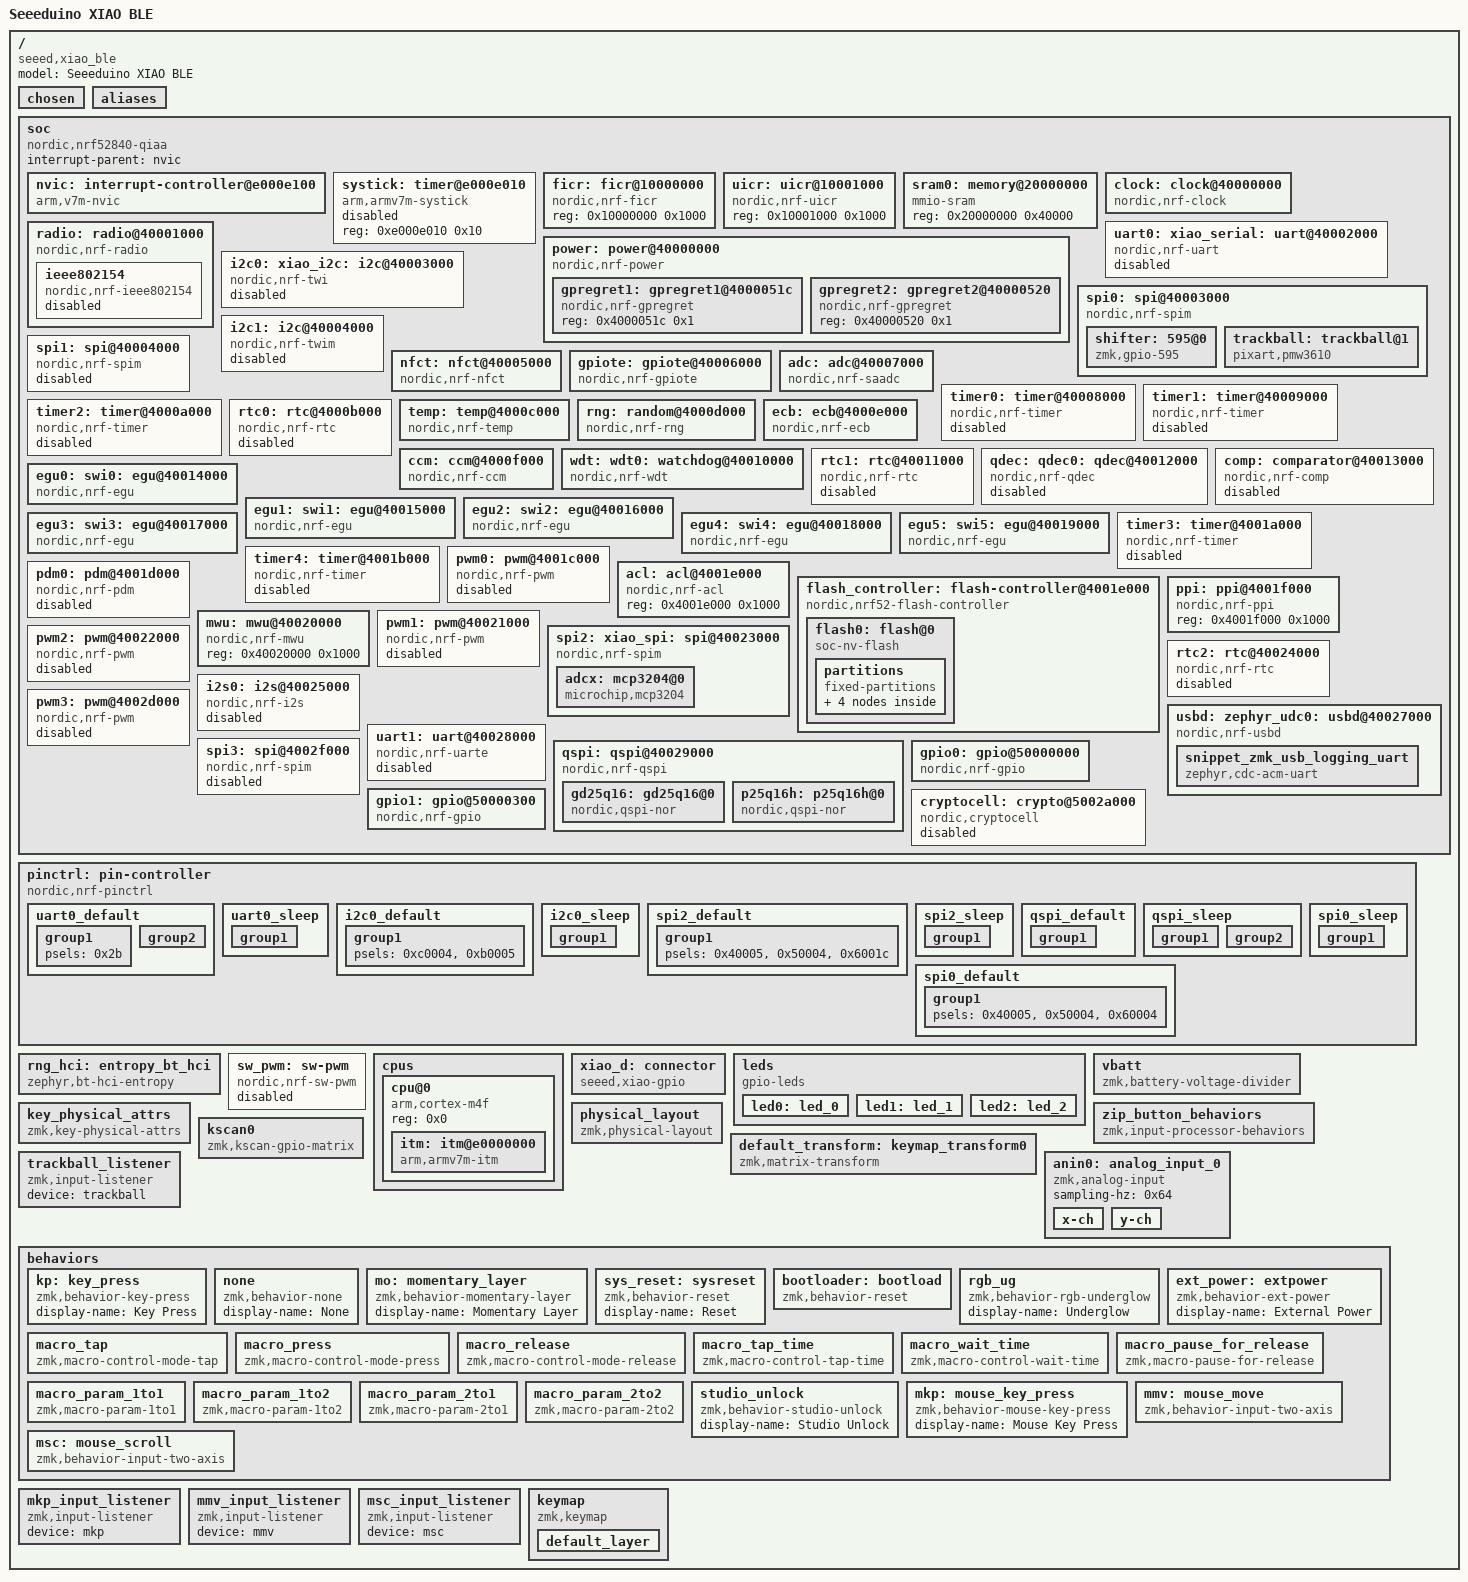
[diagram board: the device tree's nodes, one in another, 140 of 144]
/dts-v1/;

/ {
	#address-cells = < 0x1 >;
	#size-cells = < 0x1 >;
	model = "Seeeduino XIAO BLE";
	compatible = "seeed,xiao_ble";
	chosen {
		zephyr,entropy = &rng;
		zephyr,flash-controller = &flash_controller;
		zephyr,console = &snippet_zmk_usb_logging_uart;
		zephyr,shell-uart = &snippet_zmk_usb_logging_uart;
		zephyr,uart-mcumgr = &uart0;
		zephyr,bt-mon-uart = &uart0;
		zephyr,bt-c2h-uart = &uart0;
		zephyr,sram = &sram0;
		zephyr,flash = &flash0;
		zephyr,code-partition = &code_partition;
		zmk,battery = &vbatt;
		zmk,physical-layout = &physical_layout;
	};
	aliases {
		led0 = &led0;
		led1 = &led1;
		led2 = &led2;
	};
	soc {
		#address-cells = < 0x1 >;
		#size-cells = < 0x1 >;
		compatible = "nordic,nrf52840-qiaa", "nordic,nrf52840", "nordic,nrf52", "simple-bus";
		interrupt-parent = < &nvic >;
		ranges;
		nvic: interrupt-controller@e000e100 {
			#address-cells = < 0x1 >;
			compatible = "arm,v7m-nvic";
			reg = < 0xe000e100 0xc00 >;
			interrupt-controller;
			#interrupt-cells = < 0x2 >;
			arm,num-irq-priority-bits = < 0x3 >;
			phandle = < 0x1 >;
		};
		systick: timer@e000e010 {
			compatible = "arm,armv7m-systick";
			reg = < 0xe000e010 0x10 >;
			status = "disabled";
		};
		ficr: ficr@10000000 {
			compatible = "nordic,nrf-ficr";
			reg = < 0x10000000 0x1000 >;
			status = "okay";
		};
		uicr: uicr@10001000 {
			compatible = "nordic,nrf-uicr";
			reg = < 0x10001000 0x1000 >;
			status = "okay";
		};
		sram0: memory@20000000 {
			compatible = "mmio-sram";
			reg = < 0x20000000 0x40000 >;
		};
		clock: clock@40000000 {
			compatible = "nordic,nrf-clock";
			reg = < 0x40000000 0x1000 >;
			interrupts = < 0x0 0x1 >;
			status = "okay";
		};
		power: power@40000000 {
			compatible = "nordic,nrf-power";
			reg = < 0x40000000 0x1000 >;
			interrupts = < 0x0 0x1 >;
			status = "okay";
			#address-cells = < 0x1 >;
			#size-cells = < 0x1 >;
			gpregret1: gpregret1@4000051c {
				#address-cells = < 0x1 >;
				#size-cells = < 0x1 >;
				compatible = "nordic,nrf-gpregret";
				reg = < 0x4000051c 0x1 >;
				status = "okay";
			};
			gpregret2: gpregret2@40000520 {
				#address-cells = < 0x1 >;
				#size-cells = < 0x1 >;
				compatible = "nordic,nrf-gpregret";
				reg = < 0x40000520 0x1 >;
				status = "okay";
			};
		};
		radio: radio@40001000 {
			compatible = "nordic,nrf-radio";
			reg = < 0x40001000 0x1000 >;
			interrupts = < 0x1 0x1 >;
			status = "okay";
			ieee802154-supported;
			ble-2mbps-supported;
			ble-coded-phy-supported;
			tx-high-power-supported;
			ieee802154: ieee802154 {
				compatible = "nordic,nrf-ieee802154";
				status = "disabled";
			};
		};
		uart0: xiao_serial: uart@40002000 {
			compatible = "nordic,nrf-uart";
			reg = < 0x40002000 0x1000 >;
			interrupts = < 0x2 0x1 >;
			status = "disabled";
			current-speed = < 0x1c200 >;
			pinctrl-0 = < &uart0_default >;
			pinctrl-1 = < &uart0_sleep >;
			pinctrl-names = "default", "sleep";
		};
		i2c0: xiao_i2c: i2c@40003000 {
			compatible = "nordic,nrf-twi";
			#address-cells = < 0x1 >;
			#size-cells = < 0x0 >;
			reg = < 0x40003000 0x1000 >;
			clock-frequency = < 0x186a0 >;
			interrupts = < 0x3 0x1 >;
			easydma-maxcnt-bits = < 0x10 >;
			status = "disabled";
			pinctrl-0 = < &i2c0_default >;
			pinctrl-1 = < &i2c0_sleep >;
			pinctrl-names = "default", "sleep";
		};
		spi0: spi@40003000 {
			compatible = "nordic,nrf-spim";
			#address-cells = < 0x1 >;
			#size-cells = < 0x0 >;
			reg = < 0x40003000 0x1000 >;
			interrupts = < 0x3 0x1 >;
			max-frequency = < 0x7a1200 >;
			easydma-maxcnt-bits = < 0x10 >;
			status = "okay";
			pinctrl-0 = < &spi0_default >;
			pinctrl-1 = < &spi0_sleep >;
			pinctrl-names = "default", "sleep";
			cs-gpios = < &xiao_d 0x3 0x1 >, < &xiao_d 0x6 0x1 >;
			shifter: 595@0 {
				compatible = "zmk,gpio-595";
				status = "okay";
				reg = < 0x0 >;
				gpio-controller;
				spi-max-frequency = < 0x493e0 >;
				#gpio-cells = < 0x2 >;
				ngpios = < 0x20 >;
				phandle = < 0x15 >;
			};
			trackball: trackball@1 {
				compatible = "pixart,pmw3610";
				status = "okay";
				reg = < 0x1 >;
				spi-max-frequency = < 0x1e8480 >;
				irq-gpios = < &xiao_d 0x7 0x11 >;
				cpi = < 0x258 >;
				evt-type = < 0x2 >;
				x-input-code = < 0x0 >;
				y-input-code = < 0x1 >;
				phandle = < 0x16 >;
			};
		};
		i2c1: i2c@40004000 {
			compatible = "nordic,nrf-twim";
			#address-cells = < 0x1 >;
			#size-cells = < 0x0 >;
			reg = < 0x40004000 0x1000 >;
			clock-frequency = < 0x186a0 >;
			interrupts = < 0x4 0x1 >;
			easydma-maxcnt-bits = < 0x10 >;
			status = "disabled";
		};
		spi1: spi@40004000 {
			compatible = "nordic,nrf-spim";
			#address-cells = < 0x1 >;
			#size-cells = < 0x0 >;
			reg = < 0x40004000 0x1000 >;
			interrupts = < 0x4 0x1 >;
			max-frequency = < 0x7a1200 >;
			easydma-maxcnt-bits = < 0x10 >;
			status = "disabled";
		};
		nfct: nfct@40005000 {
			compatible = "nordic,nrf-nfct";
			reg = < 0x40005000 0x1000 >;
			interrupts = < 0x5 0x1 >;
			status = "okay";
		};
		gpiote: gpiote@40006000 {
			compatible = "nordic,nrf-gpiote";
			reg = < 0x40006000 0x1000 >;
			interrupts = < 0x6 0x5 >;
			status = "okay";
		};
		adc: adc@40007000 {
			compatible = "nordic,nrf-saadc";
			reg = < 0x40007000 0x1000 >;
			interrupts = < 0x7 0x1 >;
			status = "okay";
			#io-channel-cells = < 0x1 >;
			phandle = < 0x10 >;
		};
		timer0: timer@40008000 {
			compatible = "nordic,nrf-timer";
			status = "disabled";
			reg = < 0x40008000 0x1000 >;
			cc-num = < 0x4 >;
			max-bit-width = < 0x20 >;
			interrupts = < 0x8 0x1 >;
			prescaler = < 0x0 >;
		};
		timer1: timer@40009000 {
			compatible = "nordic,nrf-timer";
			status = "disabled";
			reg = < 0x40009000 0x1000 >;
			cc-num = < 0x4 >;
			max-bit-width = < 0x20 >;
			interrupts = < 0x9 0x1 >;
			prescaler = < 0x0 >;
			phandle = < 0xd >;
		};
		timer2: timer@4000a000 {
			compatible = "nordic,nrf-timer";
			status = "disabled";
			reg = < 0x4000a000 0x1000 >;
			cc-num = < 0x4 >;
			max-bit-width = < 0x20 >;
			interrupts = < 0xa 0x1 >;
			prescaler = < 0x0 >;
		};
		rtc0: rtc@4000b000 {
			compatible = "nordic,nrf-rtc";
			reg = < 0x4000b000 0x1000 >;
			cc-num = < 0x3 >;
			interrupts = < 0xb 0x1 >;
			status = "disabled";
			clock-frequency = < 0x8000 >;
			prescaler = < 0x1 >;
		};
		temp: temp@4000c000 {
			compatible = "nordic,nrf-temp";
			reg = < 0x4000c000 0x1000 >;
			interrupts = < 0xc 0x1 >;
			status = "okay";
		};
		rng: random@4000d000 {
			compatible = "nordic,nrf-rng";
			reg = < 0x4000d000 0x1000 >;
			interrupts = < 0xd 0x1 >;
			status = "okay";
		};
		ecb: ecb@4000e000 {
			compatible = "nordic,nrf-ecb";
			reg = < 0x4000e000 0x1000 >;
			interrupts = < 0xe 0x1 >;
			status = "okay";
		};
		ccm: ccm@4000f000 {
			compatible = "nordic,nrf-ccm";
			reg = < 0x4000f000 0x1000 >;
			interrupts = < 0xf 0x1 >;
			length-field-length-8-bits;
			status = "okay";
		};
		wdt: wdt0: watchdog@40010000 {
			compatible = "nordic,nrf-wdt";
			reg = < 0x40010000 0x1000 >;
			interrupts = < 0x10 0x1 >;
			status = "okay";
		};
		rtc1: rtc@40011000 {
			compatible = "nordic,nrf-rtc";
			reg = < 0x40011000 0x1000 >;
			cc-num = < 0x4 >;
			interrupts = < 0x11 0x1 >;
			status = "disabled";
			clock-frequency = < 0x8000 >;
			prescaler = < 0x1 >;
		};
		qdec: qdec0: qdec@40012000 {
			compatible = "nordic,nrf-qdec";
			reg = < 0x40012000 0x1000 >;
			interrupts = < 0x12 0x1 >;
			status = "disabled";
		};
		comp: comparator@40013000 {
			compatible = "nordic,nrf-comp";
			reg = < 0x40013000 0x1000 >;
			interrupts = < 0x13 0x1 >;
			status = "disabled";
			#io-channel-cells = < 0x1 >;
		};
		egu0: swi0: egu@40014000 {
			compatible = "nordic,nrf-egu", "nordic,nrf-swi";
			reg = < 0x40014000 0x1000 >;
			interrupts = < 0x14 0x1 >;
			status = "okay";
		};
		egu1: swi1: egu@40015000 {
			compatible = "nordic,nrf-egu", "nordic,nrf-swi";
			reg = < 0x40015000 0x1000 >;
			interrupts = < 0x15 0x1 >;
			status = "okay";
		};
		egu2: swi2: egu@40016000 {
			compatible = "nordic,nrf-egu", "nordic,nrf-swi";
			reg = < 0x40016000 0x1000 >;
			interrupts = < 0x16 0x1 >;
			status = "okay";
		};
		egu3: swi3: egu@40017000 {
			compatible = "nordic,nrf-egu", "nordic,nrf-swi";
			reg = < 0x40017000 0x1000 >;
			interrupts = < 0x17 0x1 >;
			status = "okay";
		};
		egu4: swi4: egu@40018000 {
			compatible = "nordic,nrf-egu", "nordic,nrf-swi";
			reg = < 0x40018000 0x1000 >;
			interrupts = < 0x18 0x1 >;
			status = "okay";
		};
		egu5: swi5: egu@40019000 {
			compatible = "nordic,nrf-egu", "nordic,nrf-swi";
			reg = < 0x40019000 0x1000 >;
			interrupts = < 0x19 0x1 >;
			status = "okay";
		};
		timer3: timer@4001a000 {
			compatible = "nordic,nrf-timer";
			status = "disabled";
			reg = < 0x4001a000 0x1000 >;
			cc-num = < 0x6 >;
			max-bit-width = < 0x20 >;
			interrupts = < 0x1a 0x1 >;
			prescaler = < 0x0 >;
		};
		timer4: timer@4001b000 {
			compatible = "nordic,nrf-timer";
			status = "disabled";
			reg = < 0x4001b000 0x1000 >;
			cc-num = < 0x6 >;
			max-bit-width = < 0x20 >;
			interrupts = < 0x1b 0x1 >;
			prescaler = < 0x0 >;
		};
		pwm0: pwm@4001c000 {
			compatible = "nordic,nrf-pwm";
			reg = < 0x4001c000 0x1000 >;
			interrupts = < 0x1c 0x1 >;
			status = "disabled";
			#pwm-cells = < 0x3 >;
		};
		pdm0: pdm@4001d000 {
			compatible = "nordic,nrf-pdm";
			reg = < 0x4001d000 0x1000 >;
			interrupts = < 0x1d 0x1 >;
			status = "disabled";
		};
		acl: acl@4001e000 {
			compatible = "nordic,nrf-acl";
			reg = < 0x4001e000 0x1000 >;
			status = "okay";
		};
		flash_controller: flash-controller@4001e000 {
			compatible = "nordic,nrf52-flash-controller";
			reg = < 0x4001e000 0x1000 >;
			partial-erase;
			#address-cells = < 0x1 >;
			#size-cells = < 0x1 >;
			flash0: flash@0 {
				compatible = "soc-nv-flash";
				erase-block-size = < 0x1000 >;
				write-block-size = < 0x4 >;
				reg = < 0x0 0x100000 >;
				partitions {
					compatible = "fixed-partitions";
					#address-cells = < 0x1 >;
					#size-cells = < 0x1 >;
					sd_partition: partition@0 {
						label = "softdevice";
						reg = < 0x0 0x26000 >;
					};
					code_partition: partition@27000 {
						label = "code_partition";
						reg = < 0x27000 0xc5000 >;
					};
					storage_partition: partition@ec000 {
						label = "storage";
						reg = < 0xec000 0x8000 >;
					};
					boot_partition: partition@f4000 {
						label = "adafruit_boot";
						reg = < 0xf4000 0xc000 >;
					};
				};
			};
		};
		ppi: ppi@4001f000 {
			compatible = "nordic,nrf-ppi";
			reg = < 0x4001f000 0x1000 >;
			status = "okay";
		};
		mwu: mwu@40020000 {
			compatible = "nordic,nrf-mwu";
			reg = < 0x40020000 0x1000 >;
			status = "okay";
		};
		pwm1: pwm@40021000 {
			compatible = "nordic,nrf-pwm";
			reg = < 0x40021000 0x1000 >;
			interrupts = < 0x21 0x1 >;
			status = "disabled";
			#pwm-cells = < 0x3 >;
		};
		pwm2: pwm@40022000 {
			compatible = "nordic,nrf-pwm";
			reg = < 0x40022000 0x1000 >;
			interrupts = < 0x22 0x1 >;
			status = "disabled";
			#pwm-cells = < 0x3 >;
		};
		spi2: xiao_spi: spi@40023000 {
			compatible = "nordic,nrf-spim";
			#address-cells = < 0x1 >;
			#size-cells = < 0x0 >;
			reg = < 0x40023000 0x1000 >;
			interrupts = < 0x23 0x1 >;
			max-frequency = < 0x7a1200 >;
			easydma-maxcnt-bits = < 0x10 >;
			status = "okay";
			pinctrl-0 = < &spi2_default >;
			pinctrl-1 = < &spi2_sleep >;
			pinctrl-names = "default", "sleep";
			cs-gpios = < &xiao_d 0xa 0x1 >;
			adcx: mcp3204@0 {
				compatible = "microchip,mcp3204";
				status = "okay";
				reg = < 0x0 >;
				spi-max-frequency = < 0x61a80 >;
				#io-channel-cells = < 0x1 >;
				phandle = < 0x17 >;
			};
		};
		rtc2: rtc@40024000 {
			compatible = "nordic,nrf-rtc";
			reg = < 0x40024000 0x1000 >;
			cc-num = < 0x4 >;
			interrupts = < 0x24 0x1 >;
			status = "disabled";
			clock-frequency = < 0x8000 >;
			prescaler = < 0x1 >;
		};
		i2s0: i2s@40025000 {
			compatible = "nordic,nrf-i2s";
			#address-cells = < 0x1 >;
			#size-cells = < 0x0 >;
			reg = < 0x40025000 0x1000 >;
			interrupts = < 0x25 0x1 >;
			status = "disabled";
		};
		usbd: zephyr_udc0: usbd@40027000 {
			compatible = "nordic,nrf-usbd";
			reg = < 0x40027000 0x1000 >;
			interrupts = < 0x27 0x1 >;
			num-bidir-endpoints = < 0x1 >;
			num-in-endpoints = < 0x7 >;
			num-out-endpoints = < 0x7 >;
			num-isoin-endpoints = < 0x1 >;
			num-isoout-endpoints = < 0x1 >;
			status = "okay";
			snippet_zmk_usb_logging_uart: snippet_zmk_usb_logging_uart {
				compatible = "zephyr,cdc-acm-uart";
			};
		};
		uart1: uart@40028000 {
			compatible = "nordic,nrf-uarte";
			reg = < 0x40028000 0x1000 >;
			interrupts = < 0x28 0x1 >;
			status = "disabled";
		};
		qspi: qspi@40029000 {
			compatible = "nordic,nrf-qspi";
			#address-cells = < 0x1 >;
			#size-cells = < 0x0 >;
			reg = < 0x40029000 0x1000 >, < 0x12000000 0x8000000 >;
			reg-names = "qspi", "qspi_mm";
			interrupts = < 0x29 0x1 >;
			status = "okay";
			pinctrl-0 = < &qspi_default >;
			pinctrl-1 = < &qspi_sleep >;
			pinctrl-names = "default", "sleep";
			gd25q16: gd25q16@0 {
				compatible = "nordic,qspi-nor";
				reg = < 0x0 >;
				writeoc = "pp2o";
				readoc = "read2io";
				sck-frequency = < 0xf42400 >;
				label = "GD25Q16";
				jedec-id = [ C8 40 15 ];
				size = < 0x200000 >;
				has-dpd;
				t-enter-dpd = < 0x4e20 >;
				t-exit-dpd = < 0x4e20 >;
			};
			p25q16h: p25q16h@0 {
				compatible = "nordic,qspi-nor";
				reg = < 0x0 >;
				sck-frequency = < 0x632ea00 >;
				quad-enable-requirements = "S2B1v1";
				jedec-id = [ 85 60 15 ];
				sfdp-bfp = [ E5 20 F1 FF FF FF FF 00 44 EB 08 6B 08 3B 80 BB EE FF FF FF FF FF 00 FF FF FF 00 FF 0C 20 0F 52 10 D8 08 81 ];
				size = < 0x1000000 >;
				has-dpd;
				t-enter-dpd = < 0xbb8 >;
				t-exit-dpd = < 0x1f40 >;
			};
		};
		pwm3: pwm@4002d000 {
			compatible = "nordic,nrf-pwm";
			reg = < 0x4002d000 0x1000 >;
			interrupts = < 0x2d 0x1 >;
			status = "disabled";
			#pwm-cells = < 0x3 >;
		};
		spi3: spi@4002f000 {
			compatible = "nordic,nrf-spim";
			#address-cells = < 0x1 >;
			#size-cells = < 0x0 >;
			reg = < 0x4002f000 0x1000 >;
			interrupts = < 0x2f 0x1 >;
			max-frequency = < 0x1e84800 >;
			easydma-maxcnt-bits = < 0x10 >;
			rx-delay-supported;
			rx-delay = < 0x2 >;
			status = "disabled";
		};
		gpio0: gpio@50000000 {
			compatible = "nordic,nrf-gpio";
			gpio-controller;
			reg = < 0x50000000 0x200 0x50000500 0x300 >;
			#gpio-cells = < 0x2 >;
			status = "okay";
			port = < 0x0 >;
			phandle = < 0xe >;
		};
		gpio1: gpio@50000300 {
			compatible = "nordic,nrf-gpio";
			gpio-controller;
			reg = < 0x50000300 0x200 0x50000800 0x300 >;
			#gpio-cells = < 0x2 >;
			ngpios = < 0x10 >;
			status = "okay";
			port = < 0x1 >;
			phandle = < 0xf >;
		};
		cryptocell: crypto@5002a000 {
			compatible = "nordic,cryptocell", "arm,cryptocell-310";
			reg = < 0x5002a000 0x1000 >, < 0x5002b000 0x1000 >;
			reg-names = "wrapper", "core";
			interrupts = < 0x2a 0x1 >;
			status = "disabled";
		};
	};
	pinctrl: pin-controller {
		compatible = "nordic,nrf-pinctrl";
		uart0_default: uart0_default {
			phandle = < 0x2 >;
			group1 {
				psels = < 0x2b >;
			};
			group2 {
				psels = < 0x1002c >;
				bias-pull-up;
			};
		};
		uart0_sleep: uart0_sleep {
			phandle = < 0x3 >;
			group1 {
				psels = < 0x2b >, < 0x1002c >;
				low-power-enable;
			};
		};
		i2c0_default: i2c0_default {
			phandle = < 0x4 >;
			group1 {
				psels = < 0xc0004 >, < 0xb0005 >;
			};
		};
		i2c0_sleep: i2c0_sleep {
			phandle = < 0x5 >;
			group1 {
				psels = < 0xc0004 >, < 0xb0005 >;
				low-power-enable;
			};
		};
		spi2_default: spi2_default {
			phandle = < 0x9 >;
			group1 {
				psels = < 0x40005 >, < 0x50004 >, < 0x6001c >;
			};
		};
		spi2_sleep: spi2_sleep {
			phandle = < 0xa >;
			group1 {
				psels = < 0x40005 >, < 0x50004 >, < 0x6001c >;
				low-power-enable;
			};
		};
		qspi_default: qspi_default {
			phandle = < 0xb >;
			group1 {
				psels = < 0x1d0015 >, < 0x1f0014 >, < 0x200018 >, < 0x210016 >, < 0x220017 >, < 0x1e0019 >;
			};
		};
		qspi_sleep: qspi_sleep {
			phandle = < 0xc >;
			group1 {
				psels = < 0x1d0015 >, < 0x1f0014 >, < 0x200018 >, < 0x210016 >, < 0x220017 >;
				low-power-enable;
			};
			group2 {
				psels = < 0x1e0019 >;
				low-power-enable;
				bias-pull-up;
			};
		};
		spi0_default: spi0_default {
			phandle = < 0x6 >;
			group1 {
				psels = < 0x40005 >, < 0x50004 >, < 0x60004 >;
			};
		};
		spi0_sleep: spi0_sleep {
			phandle = < 0x7 >;
			group1 {
				psels = < 0x40005 >, < 0x50004 >, < 0x60004 >;
				low-power-enable;
			};
		};
	};
	rng_hci: entropy_bt_hci {
		compatible = "zephyr,bt-hci-entropy";
		status = "okay";
	};
	sw_pwm: sw-pwm {
		compatible = "nordic,nrf-sw-pwm";
		status = "disabled";
		generator = < &timer1 >;
		clock-prescaler = < 0x0 >;
		#pwm-cells = < 0x3 >;
	};
	cpus {
		#address-cells = < 0x1 >;
		#size-cells = < 0x0 >;
		cpu@0 {
			device_type = "cpu";
			compatible = "arm,cortex-m4f";
			reg = < 0x0 >;
			#address-cells = < 0x1 >;
			#size-cells = < 0x1 >;
			itm: itm@e0000000 {
				compatible = "arm,armv7m-itm";
				reg = < 0xe0000000 0x1000 >;
				swo-ref-frequency = < 0x1e84800 >;
			};
		};
	};
	xiao_d: connector {
		compatible = "seeed,xiao-gpio";
		#gpio-cells = < 0x2 >;
		gpio-map-mask = < 0xffffffff 0xffffffc0 >;
		gpio-map-pass-thru = < 0x0 0x3f >;
		gpio-map = < 0x0 0x0 &gpio0 0x2 0x0 >, < 0x1 0x0 &gpio0 0x3 0x0 >, < 0x2 0x0 &gpio0 0x1c 0x0 >, < 0x3 0x0 &gpio0 0x1d 0x0 >, < 0x4 0x0 &gpio0 0x4 0x0 >, < 0x5 0x0 &gpio0 0x5 0x0 >, < 0x6 0x0 &gpio1 0xb 0x0 >, < 0x7 0x0 &gpio1 0xc 0x0 >, < 0x8 0x0 &gpio1 0xd 0x0 >, < 0x9 0x0 &gpio1 0xe 0x0 >, < 0xa 0x0 &gpio1 0xf 0x0 >;
		phandle = < 0x8 >;
	};
	leds {
		compatible = "gpio-leds";
		led0: led_0 {
			gpios = < &gpio0 0x1a 0x1 >;
			label = "Red LED";
		};
		led1: led_1 {
			gpios = < &gpio0 0x1e 0x1 >;
			label = "Blue LED";
		};
		led2: led_2 {
			gpios = < &gpio0 0x6 0x1 >;
			label = "Green LED";
		};
	};
	vbatt: vbatt {
		compatible = "zmk,battery-voltage-divider";
		io-channels = < &adc 0x7 >;
		power-gpios = < &gpio0 0xe 0x7 >;
		output-ohms = < 0x7c830 >;
		full-ohms = < 0x170a70 >;
	};
	zip_button_behaviors: zip_button_behaviors {
		compatible = "zmk,input-processor-behaviors";
		#input-processor-cells = < 0x0 >;
		codes = < 0x100 0x101 0x102 >;
		bindings = < &none &none &none >;
	};
	key_physical_attrs: key_physical_attrs {
		compatible = "zmk,key-physical-attrs";
		#key-cells = < 0x7 >;
		phandle = < 0x14 >;
	};
	physical_layout: physical_layout {
		compatible = "zmk,physical-layout";
		display-name = "Default Layout";
		kscan = < &kscan0 >;
		transform = < &default_transform >;
		keys = < &key_physical_attrs 0x64 0x64 0x0 0x0 0x0 0x0 0x0 >, < &key_physical_attrs 0x64 0x64 0x64 0x0 0x0 0x0 0x0 >, < &key_physical_attrs 0x64 0x64 0xc8 0x0 0x0 0x0 0x0 >, < &key_physical_attrs 0x64 0x64 0x12c 0x0 0x0 0x0 0x0 >, < &key_physical_attrs 0x64 0x64 0x190 0x0 0x0 0x0 0x0 >, < &key_physical_attrs 0x64 0x64 0x1f4 0x0 0x0 0x0 0x0 >, < &key_physical_attrs 0x64 0x64 0x258 0x0 0x0 0x0 0x0 >, < &key_physical_attrs 0x64 0x64 0x2bc 0x0 0x0 0x0 0x0 >, < &key_physical_attrs 0x64 0x64 0x0 0x64 0x0 0x0 0x0 >, < &key_physical_attrs 0x64 0x64 0x64 0x64 0x0 0x0 0x0 >, < &key_physical_attrs 0x64 0x64 0xc8 0x64 0x0 0x0 0x0 >, < &key_physical_attrs 0x64 0x64 0x12c 0x64 0x0 0x0 0x0 >, < &key_physical_attrs 0x64 0x64 0x190 0x64 0x0 0x0 0x0 >, < &key_physical_attrs 0x64 0x64 0x1f4 0x64 0x0 0x0 0x0 >, < &key_physical_attrs 0x64 0x64 0x258 0x64 0x0 0x0 0x0 >, < &key_physical_attrs 0x64 0x64 0x2bc 0x64 0x0 0x0 0x0 >, < &key_physical_attrs 0x64 0x64 0x0 0xc8 0x0 0x0 0x0 >, < &key_physical_attrs 0x64 0x64 0x64 0xc8 0x0 0x0 0x0 >, < &key_physical_attrs 0x64 0x64 0xc8 0xc8 0x0 0x0 0x0 >, < &key_physical_attrs 0x64 0x64 0x12c 0xc8 0x0 0x0 0x0 >, < &key_physical_attrs 0x64 0x64 0x190 0xc8 0x0 0x0 0x0 >, < &key_physical_attrs 0x64 0x64 0x1f4 0xc8 0x0 0x0 0x0 >, < &key_physical_attrs 0x64 0x64 0x258 0xc8 0x0 0x0 0x0 >, < &key_physical_attrs 0x64 0x64 0x2bc 0xc8 0x0 0x0 0x0 >;
	};
	default_transform: keymap_transform0 {
		compatible = "zmk,matrix-transform";
		columns = < 0x8 >;
		rows = < 0x3 >;
		map = < 0x0 0x1 0x2 0x3 0x4 0x5 0x6 0x7 0x100 0x101 0x102 0x103 0x104 0x105 0x106 0x107 0x200 0x201 0x202 0x203 0x204 0x205 0x206 0x207 >;
		phandle = < 0x13 >;
	};
	kscan0: kscan0 {
		compatible = "zmk,kscan-gpio-matrix";
		diode-direction = "col2row";
		wakeup-source;
		col-gpios = < &shifter 0x1 0x0 >, < &shifter 0x2 0x0 >, < &shifter 0x9 0x0 >, < &shifter 0xa 0x0 >, < &shifter 0x11 0x0 >, < &shifter 0x12 0x0 >, < &shifter 0x19 0x0 >, < &shifter 0x1a 0x0 >;
		row-gpios = < &xiao_d 0x0 0x20 >, < &xiao_d 0x1 0x20 >;
		phandle = < 0x12 >;
	};
	trackball_listener {
		compatible = "zmk,input-listener";
		status = "okay";
		device = < &trackball >;
	};
	anin0: analog_input_0 {
		compatible = "zmk,analog-input";
		status = "okay";
		sampling-hz = < 0x64 >;
		x-ch {
			io-channels = < &adcx 0x0 >;
			mv-mid = < 0x65e >;
			mv-min-max = < 0x640 >;
			mv-deadzone = < 0xa >;
			scale-multiplier = < 0x1 >;
			scale-divisor = < 0x46 >;
			invert;
			evt-type = < 0x2 >;
			input-code = < 0x0 >;
		};
		y-ch {
			io-channels = < &adcx 0x1 >;
			mv-mid = < 0x65e >;
			mv-min-max = < 0x640 >;
			mv-deadzone = < 0xa >;
			scale-multiplier = < 0x3 >;
			scale-divisor = < 0x4 >;
			invert;
			evt-type = < 0x2 >;
			input-code = < 0x1 >;
		};
	};
	behaviors {
		kp: key_press {
			compatible = "zmk,behavior-key-press";
			#binding-cells = < 0x1 >;
			display-name = "Key Press";
			phandle = < 0x18 >;
		};
		none: none {
			compatible = "zmk,behavior-none";
			#binding-cells = < 0x0 >;
			display-name = "None";
			phandle = < 0x11 >;
		};
		mo: momentary_layer {
			compatible = "zmk,behavior-momentary-layer";
			#binding-cells = < 0x1 >;
			display-name = "Momentary Layer";
			phandle = < 0x19 >;
		};
		sys_reset: sysreset {
			compatible = "zmk,behavior-reset";
			#binding-cells = < 0x0 >;
			display-name = "Reset";
		};
		bootloader: bootload {
			compatible = "zmk,behavior-reset";
			type = < 0x57 >;
			#binding-cells = < 0x0 >;
			display-name = "Bootloader";
		};
		rgb_ug: rgb_ug {
			compatible = "zmk,behavior-rgb-underglow";
			#binding-cells = < 0x2 >;
			display-name = "Underglow";
		};
		ext_power: extpower {
			compatible = "zmk,behavior-ext-power";
			#binding-cells = < 0x1 >;
			display-name = "External Power";
		};
		macro_tap: macro_tap {
			compatible = "zmk,macro-control-mode-tap";
			#binding-cells = < 0x0 >;
		};
		macro_press: macro_press {
			compatible = "zmk,macro-control-mode-press";
			#binding-cells = < 0x0 >;
		};
		macro_release: macro_release {
			compatible = "zmk,macro-control-mode-release";
			#binding-cells = < 0x0 >;
		};
		macro_tap_time: macro_tap_time {
			compatible = "zmk,macro-control-tap-time";
			#binding-cells = < 0x1 >;
		};
		macro_wait_time: macro_wait_time {
			compatible = "zmk,macro-control-wait-time";
			#binding-cells = < 0x1 >;
		};
		macro_pause_for_release: macro_pause_for_release {
			compatible = "zmk,macro-pause-for-release";
			#binding-cells = < 0x0 >;
		};
		macro_param_1to1: macro_param_1to1 {
			compatible = "zmk,macro-param-1to1";
			#binding-cells = < 0x0 >;
		};
		macro_param_1to2: macro_param_1to2 {
			compatible = "zmk,macro-param-1to2";
			#binding-cells = < 0x0 >;
		};
		macro_param_2to1: macro_param_2to1 {
			compatible = "zmk,macro-param-2to1";
			#binding-cells = < 0x0 >;
		};
		macro_param_2to2: macro_param_2to2 {
			compatible = "zmk,macro-param-2to2";
			#binding-cells = < 0x0 >;
		};
		studio_unlock: studio_unlock {
			compatible = "zmk,behavior-studio-unlock";
			#binding-cells = < 0x0 >;
			display-name = "Studio Unlock";
		};
		mkp: mouse_key_press {
			compatible = "zmk,behavior-mouse-key-press";
			#binding-cells = < 0x1 >;
			display-name = "Mouse Key Press";
			phandle = < 0x1a >;
		};
		mmv: mouse_move {
			compatible = "zmk,behavior-input-two-axis";
			#binding-cells = < 0x1 >;
			x-input-code = < 0x0 >;
			y-input-code = < 0x1 >;
			time-to-max-speed-ms = < 0x12c >;
			acceleration-exponent = < 0x1 >;
			phandle = < 0x1b >;
		};
		msc: mouse_scroll {
			compatible = "zmk,behavior-input-two-axis";
			#binding-cells = < 0x1 >;
			x-input-code = < 0x6 >;
			y-input-code = < 0x8 >;
			time-to-max-speed-ms = < 0x12c >;
			acceleration-exponent = < 0x0 >;
			phandle = < 0x1c >;
		};
	};
	mkp_input_listener: mkp_input_listener {
		compatible = "zmk,input-listener";
		device = < &mkp >;
	};
	mmv_input_listener: mmv_input_listener {
		compatible = "zmk,input-listener";
		device = < &mmv >;
	};
	msc_input_listener: msc_input_listener {
		compatible = "zmk,input-listener";
		device = < &msc >;
	};
	keymap {
		compatible = "zmk,keymap";
		default_layer {
			bindings = < &kp 0x7001e &kp 0x7001f &kp 0x70004 &kp 0x70005 >;
		};
	};
};
